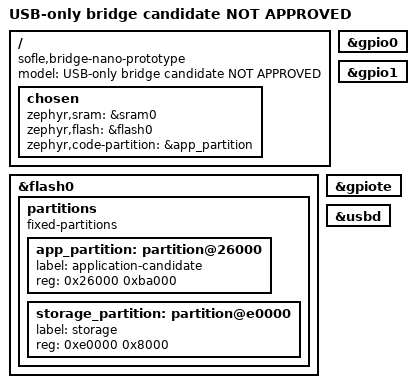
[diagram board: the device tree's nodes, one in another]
/* SPDX-License-Identifier: MIT
 * Compile-only candidate. NOT an approved flash layout. No UICR/regulator writes.
 * 0x26000 is the observed third-controller application's vector address.
 * Settings location is a NEW conservative candidate, not inferred from CURRENT.UF2.
 */
/dts-v1/;
#include <nordic/nrf52840_qiaa.dtsi>
/ {
    model = "USB-only bridge candidate NOT APPROVED";
    compatible = "sofle,bridge-nano-prototype";
    chosen {
        zephyr,sram = &sram0;
        zephyr,flash = &flash0;
        zephyr,code-partition = &app_partition;
    };
};
&flash0 {
    partitions {
        compatible = "fixed-partitions";
        #address-cells = <1>;
        #size-cells = <1>;
        app_partition: partition@26000 {
            label = "application-candidate";
            reg = <0x26000 0xba000>;
        };
        storage_partition: partition@e0000 {
            label = "storage";
            reg = <0xe0000 0x8000>;
        };
    };
};
&gpio0 { status = "okay"; };
&gpio1 { status = "okay"; };
&gpiote { status = "okay"; };
zephyr_udc0: &usbd { status = "okay"; };
